# STM32WBA65 register map
File version: 1.0
CPU: CM33 r0p1, little endian, MPU, FPU, 4 interrupt priority bits
Registers are 32-bit, read-write, reset 0x0 unless marked. A register's access mark holds for its fields unless they carry their own. Offsets are from the block's base; [hi:lo] are bit positions; {n}, {i} and the like mark numbered series; 'fields as' and 'values as' point back to an identical list.

## AES — AES register block
Base 0x420C0000
Same registers: SEC_AES 0x520C0000
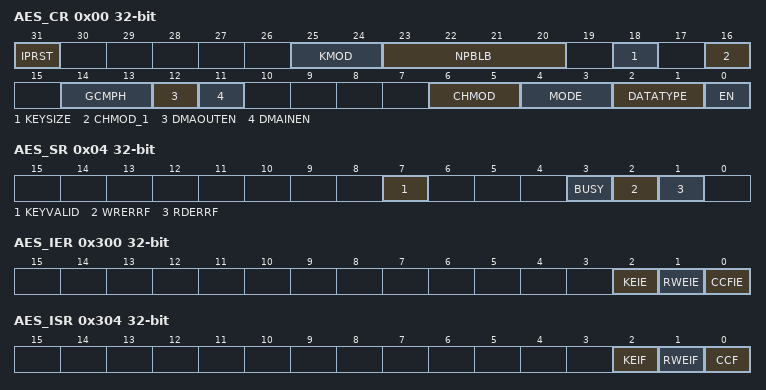
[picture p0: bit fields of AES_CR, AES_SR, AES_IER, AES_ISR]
0x00 AES_CR — AES control register
  [31] IPRST — AES peripheral software reset
  [25:24] KMOD — Key mode selection
    0=Normal key mode; 2=Shared key mode
  [23:20] NPBLB — Number of padding bytes in last block
    0=All bytes are valid (no padding); 1=Padding for the last LSB byte; 15=Padding for the 15 LSB bytes of last block
  [18] KEYSIZE — Key size selection
    0=128-bit; 1=256-bit
  [16] CHMOD_1 — CHMOD[2]
  [14:13] GCMPH — GCM or CCM phase selection
    0=Initialization phase; 1=Header phase; 2=Payload phase; 3=Final phase
  [12] DMAOUTEN — DMA output enable
    0=Disable; 1=Enable
  [11] DMAINEN — DMA input enable
    0=Disable; 1=Enable
  [6:5] CHMOD — CHMOD[1:0]: Chaining mode
    0=Electronic codebook (ECB); 1=Cipher-block chaining (CBC); 2=Counter mode (CTR); 3=Galois counter mode (GCM) and Galois message authentication code (GMAC)
  [4:3] MODE — Operating mode
    0=Encryption; 1=Key derivation (or key preparation), for ECB/CBC decryption only; 2=Decryption
  [2:1] DATATYPE
    0=No swapping (32-bit data); 1=Half-word swapping (16-bit data); 2=Byte swapping (8-bit data); 3=Bit-level swapping
  [0] EN — Enable
    0=Disable; 1=Enable
0x04 AES_SR ro — AES status register
  [7] KEYVALID — Key valid flag
    0=Key not valid; 1=Key valid
  [3] BUSY
    0=Idle; 1=Busy
  [2] WRERRF — Write error flag
    0=No error; 1=Unexpected write to AES_DINR register occurred during computation or data output phase
  [1] RDERRF — Read error flag
    0=No error; 1=Unexpected read to AES_DOUTR register occurred during computation or data input phase
0x08 AES_DINR wo — AES data input register
  [31:0] DIN — Data input
0x0C AES_DOUTR ro — AES data output register
  [31:0] DOUT — Data output
{0x10+4i} AES_KEYR{i} wo (i=0..3) — AES key register {i}
  [31:0] KEY — Cryptographic key, bits [{32i+31}:{32i}]
{0x20+4i} AES_IVR{i} (i=0..3) — AES initialization vector register {i}
  [31:0] IVI — Initialization vector input, bits [{32i+31}:{32i}]
{0x20+4i} AES_KEYR{i} wo (i=4..7) — AES key register {i}
  [31:0] KEY — Cryptographic key, bits [{32i+31}:{32i}]
{0x40+4i} AES_SUSPR{i} (i=0..7) — AES suspend registers
  [31:0] SUSP — Suspend data
0x300 AES_IER — AES interrupt enable register
  [all] fields
    0=Disabled (masked); 1=Enabled (not masked)
  [2] KEIE — Key error interrupt enable
  [1] RWEIE — Read or write error interrupt enable
  [0] CCFIE — Computation complete flag interrupt enable
0x304 AES_ISR ro — AES interrupt status register
  [2] KEIF — Key error interrupt flag
    0=No key error detected; 1=Key information failed to load into key registers
  [1] RWEIF — Read or write error interrupt flag
    0=No read or write error detected; 1=Read or write error detected
  [0] CCF — Computation complete flag
    0=Not completed; 1=Completed
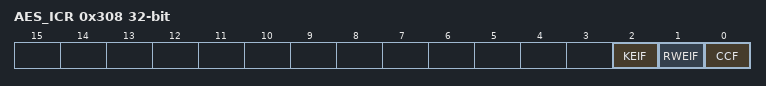
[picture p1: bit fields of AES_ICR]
0x308 AES_ICR wo — AES interrupt clear register
  [2] KEIF — Key error interrupt flag clear
  [1] RWEIF — Read or write error interrupt flag clear
  [0] CCF — Computation complete flag clear

## COMP — COMP address block description
Base 0x46005400
Same registers: SEC_COMP 0x56005400
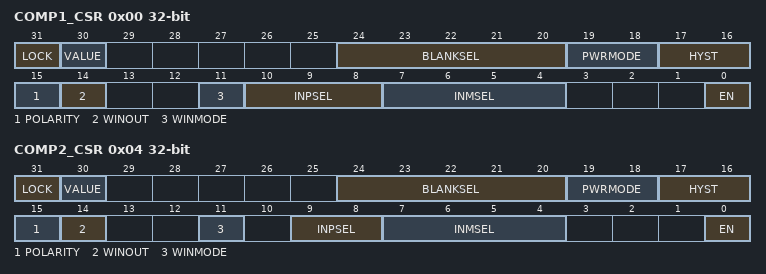
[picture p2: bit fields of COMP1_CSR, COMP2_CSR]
0x00 COMP1_CSR — COMP1 control and status register
  [31] LOCK — COMP1_CSR register lock
    0=COMP1_CSR read/write bits can be written by software; 1=COMP1_CSR bits can be read but not written by software
  [30] VALUE ro — COMP1 output status
  [24:20] BLANKSEL — COMP1 blanking source selector
    0=None (no blanking)
  [19:18] PWRMODE — COMP1 power mode selector
    0=High speed; 1=Intermediate speed and power; 2=Medium speed and power; 3=Ultra-low-power
  [17:16] HYST — COMP1 hysteresis selector
    0=None; 1=Low hysteresis; 2=Medium hysteresis; 3=High hysteresis
  [15] POLARITY — COMP1 polarity selector
    0=Noninverted; 1=Inverted
  [14] WINOUT — COMP1 output selector
    0=COMP1_VALUE; 1=COMP1_VALUE XOR COMP2_VALUE (required for window mode, see Figure103)
  [11] WINMODE — COMP1 noninverting input selector for window mode
    0=Signal selected with INPSEL[1:0]; 1=COMP2_INP signal of COMP2 (required for window mode, see Figure103)
  [10:8] INPSEL — COMP1 signal selector for noninverting input
  [7:4] INMSEL — COMP1 signal selector for inverting input INM
  [0] EN — COMP1 enable
    0=COMP1 disabled; 1=COMP1 enabled
0x04 COMP2_CSR — COMP2 control and status register
  [31] LOCK — COMP2_CSR register lock
    0=COMP2_CSR read/write bits can be written by software; 1=COMP2_CSR bits can be read but not written by software
  [30] VALUE ro — COMP2 output status
  [24:20] BLANKSEL — COMP2 blanking source selector
    0=None (no blanking)
  [19:18] PWRMODE — COMP2 power mode selector
    values as COMP1_CSR.PWRMODE
  [17:16] HYST — COMP2 hysteresis selector
    values as COMP1_CSR.HYST
  [15] POLARITY — COMP2 polarity selector
    0=Noninverted; 1=Inverted
  [14] WINOUT — COMP2 output selector
    0=COMP2_VALUE; 1=COMP1_VALUE XOR COMP2_VALUE (required for window mode, see Figure103)
  [11] WINMODE — COMP2 noninverting input selector for window mode
    0=Signal selected with INPSEL[1:0]; 1=COMP1_INP signal of COMP1 (required for window mode, see Figure103)
  [9:8] INPSEL — COMP2 signal selector for noninverting input
  [7:4] INMSEL — COMP2 signal selector for inverting input INM
  [0] EN — COMP2 enable
    0=COMP2 disabled; 1=COMP2 enabled

## Notices in the file
Copyright (c) 2025 STMicroelectronics.
SPDX-License-Identifier: Apache-2.0
Licensed under the Apache License, Version 2.0 (the "License");
you may not use this file except in compliance with the License.
You may obtain a copy of the License at
http://www.apache.org/licenses/LICENSE-2.0
Unless required by applicable law or agreed to in writing, software
distributed under the License is distributed on an "AS IS" BASIS,
WITHOUT WARRANTIES OR CONDITIONS OF ANY KIND, either express or implied.
See the License for the specific language governing permissions and
limitations under the License.
